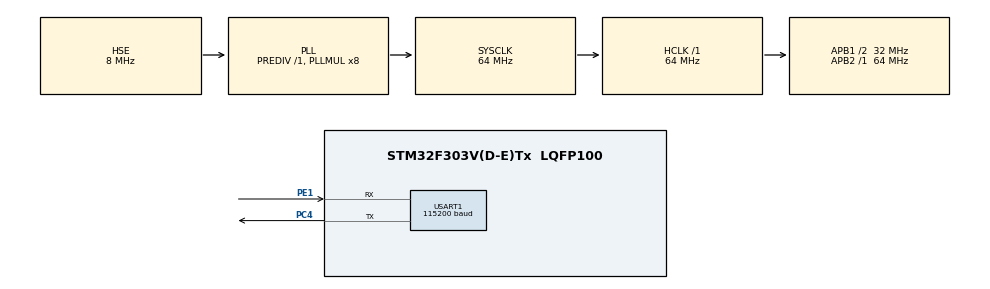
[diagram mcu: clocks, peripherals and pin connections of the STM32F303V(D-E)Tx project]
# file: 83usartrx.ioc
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Mcu.Family=STM32F3
Mcu.Name=STM32F303V(D-E)Tx
Mcu.Package=LQFP100
NVIC.PriorityGroup=NVIC_PRIORITYGROUP_4
NVIC.USART1_IRQn=true\:0\:0\:false\:false\:true\:true\:true\:true
PA13.Mode=Serial_Wire
PA13.Signal=SYS_JTMS-SWDIO
PA14.Mode=Serial_Wire
PA14.Signal=SYS_JTCK-SWCLK
PC4.Mode=Asynchronous
PC4.Signal=USART1_TX
PE1.Mode=Asynchronous
PE1.Signal=USART1_RX
PF0-OSC_IN.Mode=HSE-External-Oscillator
PF0-OSC_IN.Signal=RCC_OSC_IN
PF1-OSC_OUT.Mode=HSE-External-Oscillator
PF1-OSC_OUT.Signal=RCC_OSC_OUT
ProjectManager.HeapSize=0x200
ProjectManager.StackSize=0x400
ProjectManager.TargetToolchain=STM32CubeIDE
RCC.AHBFreq_Value=64000000
RCC.APB1CLKDivider=RCC_HCLK_DIV2
RCC.APB1Freq_Value=32000000
RCC.APB1TimFreq_Value=64000000
RCC.APB2Freq_Value=64000000
RCC.APB2TimFreq_Value=64000000
RCC.CortexFreq_Value=64000000
RCC.HCLKFreq_Value=64000000
RCC.HSE_VALUE=8000000
RCC.HSI_VALUE=8000000
RCC.LSE_VALUE=32768
RCC.PLLMUL=RCC_PLL_MUL8
RCC.PLLSourceVirtual=RCC_PLLSOURCE_HSE
RCC.SYSCLKFreq_VALUE=64000000
RCC.SYSCLKSourceVirtual=RCC_SYSCLKSOURCE_PLLCLK
RCC.USBFreq_Value=64000000
USART1.BaudRate=115200
USART1.VirtualMode-Asynchronous=VM_ASYNC
board=custom

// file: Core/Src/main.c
/* USER CODE BEGIN Header */
/**
  ******************************************************************************
  * @file           : main.c
  * @brief          : Main program body
  ******************************************************************************
  * @attention
  *
  * Copyright (c) 2022 STMicroelectronics.
  * All rights reserved.
  *
  * This software is licensed under terms that can be found in the LICENSE file
  * in the root directory of this software component.
  * If no LICENSE file comes with this software, it is provided AS-IS.
  *
  ******************************************************************************
  */
/* USER CODE END Header */
#include "main.h"

UART_HandleTypeDef huart1;

/* USER CODE BEGIN PV */
uint8_t Rx_Data[10]={0,0,0,0,0,0,0,0,0,0};
/* USER CODE END PV */

void SystemClock_Config(void);
static void MX_GPIO_Init(void);
static void MX_USART1_UART_Init(void);

/* USER CODE BEGIN 0 */
#ifdef __GNUC__
#define PUTCHAR_PROTOTYPE int __io_putchar(int ch)
#else
#define PUTCHAR_PROTOTYPE int fputc(int ch, FILE *f)
#endif

PUTCHAR_PROTOTYPE
{

	HAL_UART_Transmit(&huart1,(uint8_t*)&ch, 1, 0xFFFF);
	return ch;
}
/* USER CODE END 0 */

int main(void)
{

  /* MCU Configuration--------------------------------------------------------*/

  /* Reset of all peripherals, Initializes the Flash interface and the Systick. */
  HAL_Init();

  /* Configure the system clock */
  SystemClock_Config();

  /* Initialize all configured peripherals */
  MX_GPIO_Init();
  MX_USART1_UART_Init();
  /* USER CODE BEGIN 2 */
  HAL_UART_Receive_IT(&huart1, (uint8_t *)Rx_Data, 10); //�?启接收中断，接收10个数据到Rx_Data
  /* USER CODE END 2 */

  /* Infinite loop */
  /* USER CODE BEGIN WHILE */
  while (1)
  {
	/*
	 * 轮询方式接收

	  uint8_t rxdata1[10]={0,0,0,0,0,0,0,0,0,0};// 判断是否接收成功

      if(HAL_UART_Receive(&huart1, rxdata1, 10, 10000) == HAL_OK)
      {

          HAL_UART_Transmit(&huart1,rxdata1, 10, 0xffff);// 将接收成功的数据通过串口发出�??
      }
    */
    /* USER CODE END WHILE */
	  printf("Hello World!\n");
	  HAL_Delay(1000);
  }
}

void SystemClock_Config(void)
{
  RCC_OscInitTypeDef RCC_OscInitStruct = {0};
  RCC_ClkInitTypeDef RCC_ClkInitStruct = {0};
  RCC_PeriphCLKInitTypeDef PeriphClkInit = {0};

  /** Initializes the RCC Oscillators according to the specified parameters
  * in the RCC_OscInitTypeDef structure.
  */
  RCC_OscInitStruct.OscillatorType = RCC_OSCILLATORTYPE_HSE;
  RCC_OscInitStruct.HSEState = RCC_HSE_ON;
  RCC_OscInitStruct.HSIState = RCC_HSI_ON;
  RCC_OscInitStruct.PLL.PLLState = RCC_PLL_ON;
  RCC_OscInitStruct.PLL.PLLSource = RCC_PLLSOURCE_HSE;
  RCC_OscInitStruct.PLL.PLLMUL = RCC_PLL_MUL8;
  RCC_OscInitStruct.PLL.PREDIV = RCC_PREDIV_DIV1;
  if (HAL_RCC_OscConfig(&RCC_OscInitStruct) != HAL_OK)
  {
    Error_Handler();
  }

  /** Initializes the CPU, AHB and APB buses clocks
  */
  RCC_ClkInitStruct.ClockType = RCC_CLOCKTYPE_HCLK|RCC_CLOCKTYPE_SYSCLK
                              |RCC_CLOCKTYPE_PCLK1|RCC_CLOCKTYPE_PCLK2;
  RCC_ClkInitStruct.SYSCLKSource = RCC_SYSCLKSOURCE_PLLCLK;
  RCC_ClkInitStruct.AHBCLKDivider = RCC_SYSCLK_DIV1;
  RCC_ClkInitStruct.APB1CLKDivider = RCC_HCLK_DIV2;
  RCC_ClkInitStruct.APB2CLKDivider = RCC_HCLK_DIV1;

  if (HAL_RCC_ClockConfig(&RCC_ClkInitStruct, FLASH_LATENCY_2) != HAL_OK)
  {
    Error_Handler();
  }
  PeriphClkInit.PeriphClockSelection = RCC_PERIPHCLK_USART1;
  PeriphClkInit.Usart1ClockSelection = RCC_USART1CLKSOURCE_PCLK2;
  if (HAL_RCCEx_PeriphCLKConfig(&PeriphClkInit) != HAL_OK)
  {
    Error_Handler();
  }
}

static void MX_USART1_UART_Init(void)
{

  huart1.Instance = USART1;
  huart1.Init.BaudRate = 115200;
  huart1.Init.WordLength = UART_WORDLENGTH_8B;
  huart1.Init.StopBits = UART_STOPBITS_1;
  huart1.Init.Parity = UART_PARITY_NONE;
  huart1.Init.Mode = UART_MODE_TX_RX;
  huart1.Init.HwFlowCtl = UART_HWCONTROL_NONE;
  huart1.Init.OverSampling = UART_OVERSAMPLING_16;
  huart1.Init.OneBitSampling = UART_ONE_BIT_SAMPLE_DISABLE;
  huart1.AdvancedInit.AdvFeatureInit = UART_ADVFEATURE_NO_INIT;
  if (HAL_UART_Init(&huart1) != HAL_OK)
  {
    Error_Handler();
  }

}

static void MX_GPIO_Init(void)
{

  /* GPIO Ports Clock Enable */
  __HAL_RCC_GPIOF_CLK_ENABLE();
  __HAL_RCC_GPIOC_CLK_ENABLE();
  __HAL_RCC_GPIOA_CLK_ENABLE();
  __HAL_RCC_GPIOE_CLK_ENABLE();

}

/* USER CODE BEGIN 4 */
void HAL_UART_RxCpltCallback(UART_HandleTypeDef *huart)
{
	/* 将接收成功的数据通过串口发出*/
	if(huart->Instance == USART1){
		HAL_UART_Transmit(&huart1,Rx_Data, 10, 0xffff);
		HAL_UART_Receive_IT(&huart1, (uint8_t *)Rx_Data, 10); //重新�?启，接收10个数据到Rx_Data
	}

}
/* USER CODE END 4 */

void Error_Handler(void)
{
  __disable_irq();
  while (1)
  {
  }
}
